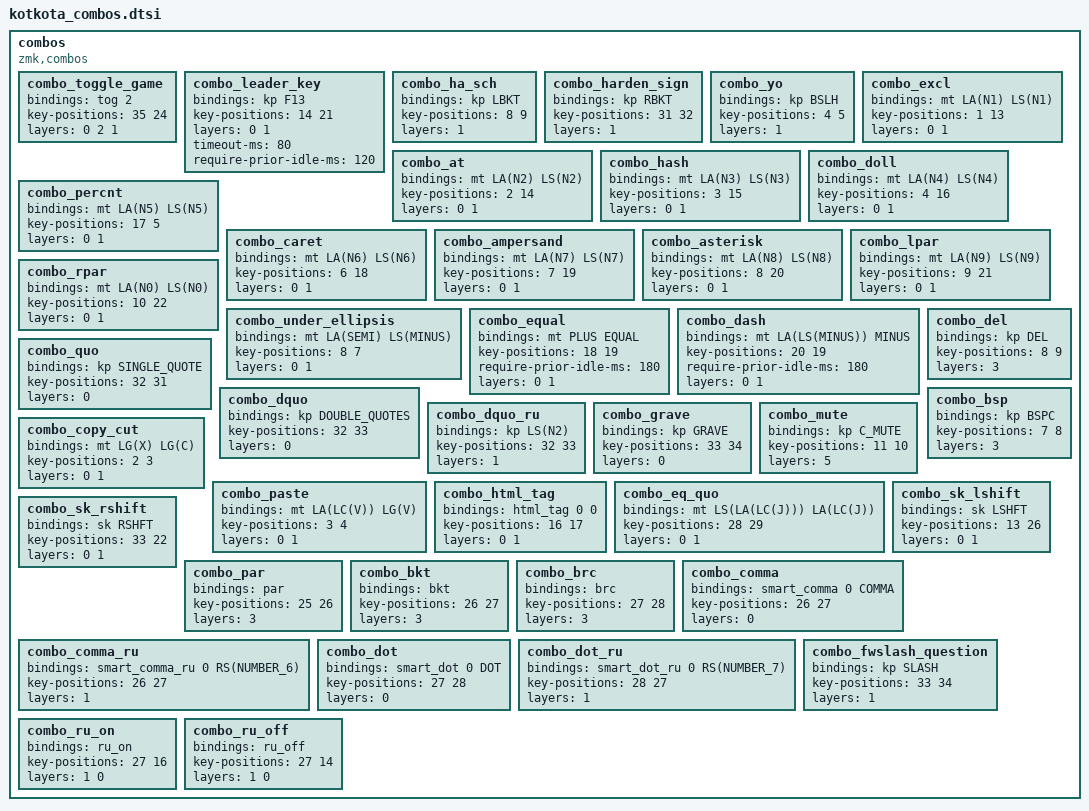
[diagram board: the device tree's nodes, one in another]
combos {
  compatible = "zmk,combos";

  combo_toggle_game {
    bindings = <&tog 2>;
    key-positions = <35 24>;
    layers = <0 2 1>;
  };

  combo_leader_key {
    bindings = <&kp F13>;
    key-positions = <14 21>;
    layers = <0 1>;
    timeout-ms = <80>;
    require-prior-idle-ms = <120>;
  };

  combo_ha_sch {
    bindings = <&kp LBKT>;
    key-positions = <8 9>;
    layers = <1>;
  };

  combo_harden_sign {
    bindings = <&kp RBKT>;
    key-positions = <31 32>;
    layers = <1>;
  };

  combo_yo {
    bindings = <&kp BSLH>;
    key-positions = <4 5>;
    layers = <1>;
  };

  combo_excl {
    bindings = <&mt LA(N1) LS(N1)>;
    key-positions = <1 13>;
    layers = <0 1>;
  };

  combo_at {
    bindings = <&mt LA(N2) LS(N2)>;
    key-positions = <2 14>;
    layers = <0 1>;
  };

  combo_hash {
    bindings = <&mt LA(N3) LS(N3)>;
    key-positions = <3 15>;
    layers = <0 1>;
  };

  combo_doll {
    bindings = <&mt LA(N4) LS(N4)>;
    key-positions = <4 16>;
    layers = <0 1>;
  };

  combo_percnt {
    bindings = <&mt LA(N5) LS(N5)>;
    key-positions = <17 5>;
    layers = <0 1>;
  };

  combo_caret {
    bindings = <&mt LA(N6) LS(N6)>;
    key-positions = <6 18>;
    layers = <0 1>;
  };

  combo_ampersand {
    bindings = <&mt LA(N7) LS(N7)>;
    key-positions = <7 19>;
    layers = <0 1>;
  };

  combo_asterisk {
    bindings = <&mt LA(N8) LS(N8)>;
    key-positions = <8 20>;
    layers = <0 1>;
  };

  combo_lpar {
    bindings = <&mt LA(N9) LS(N9)>;
    key-positions = <9 21>;
    layers = <0 1>;
  };

  combo_rpar {
    bindings = <&mt LA(N0) LS(N0)>;
    key-positions = <10 22>;
    layers = <0 1>;
  };

  combo_under_ellipsis {
    bindings = <&mt LA(SEMI) LS(MINUS)>;
    key-positions = <8 7>;
    layers = <0 1>;
  };

  combo_equal {
    bindings = <&mt PLUS EQUAL>;
    key-positions = <18 19>;
    require-prior-idle-ms = <180>;
    layers = <0 1>;
  };

  combo_dash {
    bindings = <&mt LA(LS(MINUS)) MINUS>;
    key-positions = <20 19>;
    require-prior-idle-ms = <180>;
    layers = <0 1>;
  };

  combo_quo {
    bindings = <&kp SINGLE_QUOTE>;
    key-positions = <32 31>;
    layers = <0>;
  };

  combo_dquo {
    bindings = <&kp DOUBLE_QUOTES>;
    key-positions = <32 33>;
    layers = <0>;
  };

  combo_dquo_ru {
    bindings = <&kp LS(N2)>;
    key-positions = <32 33>;
    layers = <1>;
  };

  combo_grave {
    bindings = <&kp GRAVE>;
    key-positions = <33 34>;
    layers = <0>;
  };

  combo_del {
    bindings = <&kp DEL>;
    key-positions = <8 9>;
    layers = <3>;
  };

  combo_bsp {
    bindings = <&kp BSPC>;
    key-positions = <7 8>;
    layers = <3>;
  };

  combo_mute {
    bindings = <&kp C_MUTE>;
    key-positions = <11 10>;
    layers = <5>;
  };

  combo_copy_cut {
    bindings = <&mt LG(X) LG(C)>;
    key-positions = <2 3>;
    layers = <0 1>;
  };

  combo_paste {
    bindings = <&mt LA(LC(V)) LG(V)>;
    key-positions = <3 4>;
    layers = <0 1>;
  };

  combo_html_tag {
    bindings = <&html_tag 0 0>;
    key-positions = <16 17>;
    layers = <0 1>;
  };

  combo_eq_quo {
    bindings = <&mt LS(LA(LC(J))) LA(LC(J))>;
    key-positions = <28 29>;
    layers = <0 1>;
  };

  combo_sk_lshift {
    bindings = <&sk LSHFT>;
    key-positions = <13 26>;
    layers = <0 1>;
  };

  combo_sk_rshift {
    bindings = <&sk RSHFT>;
    key-positions = <33 22>;
    layers = <0 1>;
  };

  combo_par {
    bindings = <&par>;
    key-positions = <25 26>;
    layers = <3>;
  };

  combo_bkt {
    bindings = <&bkt>;
    key-positions = <26 27>;
    layers = <3>;
  };

  combo_brc {
    bindings = <&brc>;
    key-positions = <27 28>;
    layers = <3>;
  };

  combo_comma {
    bindings = <&smart_comma 0 COMMA>;
    key-positions = <26 27>;
    layers = <0>;
  };

  combo_comma_ru {
    bindings = <&smart_comma_ru 0 RS(NUMBER_6)>;
    key-positions = <26 27>;
    layers = <1>;
  };

  combo_dot {
    bindings = <&smart_dot 0 DOT>;
    key-positions = <27 28>;
    layers = <0>;
  };

  combo_dot_ru {
    bindings = <&smart_dot_ru 0 RS(NUMBER_7)>;
    key-positions = <28 27>;
    layers = <1>;
  };

  combo_fwslash_question {
    bindings = <&kp SLASH>;
    key-positions = <33 34>;
    layers = <1>;
  };

  combo_ru_on {
    bindings = <&ru_on>;
    key-positions = <27 16>;
    layers = <1 0>;
  };

  combo_ru_off {
    bindings = <&ru_off>;
    key-positions = <27 14>;
    layers = <1 0>;
  };
};
